# R7FA6T2BD register map
Vendor: Renesas Electronics Corporation; Series: RA6; File version: 1.30.01
CPU: CM33 r0p4, little endian, MPU, FPU, VTOR, 4 interrupt priority bits, 96 interrupts
Registers are 32-bit, read-write, reset 0x0 unless marked. A register's access mark holds for its fields unless they carry their own. Offsets are from the block's base; [hi:lo] are bit positions; {n}, {i} and the like mark numbered series; 'fields as' and 'values as' point back to an identical list.

## POEG — Port Output Enable for GPT
Base 0x4008A000
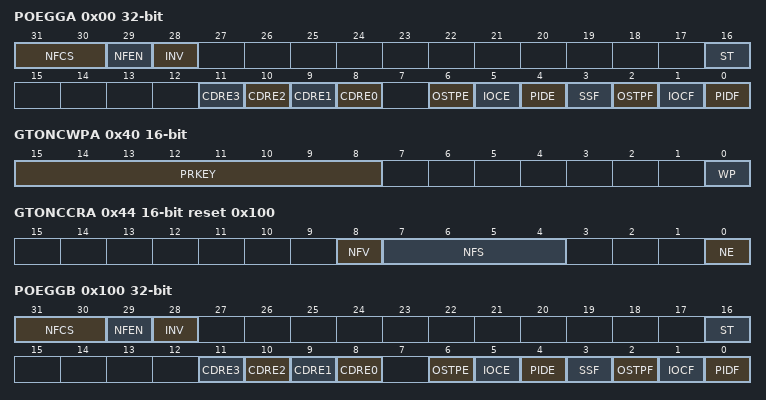
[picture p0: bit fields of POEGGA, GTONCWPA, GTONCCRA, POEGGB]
0x00 POEGGA — POEG Group A Setting Register
  [31:30] NFCS — Noise filter Clock Select
    0=Samples the input level of GTETRGn pin three times per PCLKB/1 clock; 1=Samples the input level of GTETRGn pin three times per PCLKB/8 clock; 2=Samples the input level of GTETRGn pin three times per PCLKB/32 clock; 3=Samples the input level of GTETRGn pin three times per PCLKB/128 clock
  [29] NFEN — Noise filter Enable
    0=Digital noise filter on the GTETRGn pin is disabled; 1=Digital noise filter on the GTETRGn pin is enabled
  [28] INV — GTETRGn Input Inverting
    0=Input on the GTETRGn pin is not inverted; 1=Input on the GTETRGn pin is inverted
  [16] ST ro — GTETRGn Input Status Flag
    0=The corresponding external trigger for output to the GPT is 0; 1=The corresponding external trigger for output to the GPT is 1
  [n+8] CDRE{n} (n=0..3) — ACMPHS{n} Enable
    0=Comparator edge detection {n} is disabled; 1=Comparator edge detection {n} is enabled
  [6] OSTPE — Enable Stopping Output on Stopping of Oscillation
    0=Detection of stopping of oscillation is disabled; 1=Detection of stopping of oscillation is enabled
  [5] IOCE — GPT Output Stop Request Enable
    0=Detection of stopping of output from the GPT is disabled; 1=Detection of stopping of output from the GPT is enabled
  [4] PIDE — Port Input Detection Enable
    0=Detection of input levels on the corresponding GTETRGn pin is disabled; 1=Detection of input levels on the corresponding GTETRGn pin is enabled
  [3] SSF — Software Stop Flag
    0=Software has not stopped output; 1=Software has stopped output
  [2] OSTPF — Oscillation Stop Detection Flag
    0=Stopping of oscillation was not detected; 1=Stopping of oscillation was detected
  [1] IOCF — GPT or ACMPHS Output Stop Request Detection Flag
    0=Neither stopping of GPT output nor a comparator edge was detected; 1=Either stopping of GPT output or comparator edge was detected
  [0] PIDF — Port Input Detection Flag
    0=The selected input level was not detected on the GTETRGn pin; 1=The selected input level was detected on the GTETRGn pin
0x40 GTONCWPA 16-bit — GPT Output Stopping Control Group A Write Protection Register
  [15:8] PRKEY — Key Code
  [0] WP — Register Writing Disable
    0=Writing to the GTONCCRn register is enabled; 1=Writing to the GTONCCRn register is disabled
0x44 GTONCCRA 16-bit reset 0x100 — GPT Output Stopping Control Group A Controlling Register
  [8] NFV — Direct Stopping Request Active Sense
    0=Stopping output is requested when the output stopping detection signal is 0; 1=Stopping output is requested when the output stopping detection signal is 1
  [7:4] NFS — Direct Stopping Request Selection
    0=Comparator level detection 0; 1=Comparator level detection 1; 2=Comparator level detection 2; 4=Comparator level detection 3; 7=GTETRGn pin input level detection (n = A to D); other=Others (Setting prohibited)
  [0] NE — Direct Stopping Request Setting
    0=The signal for detection is not set as a direct stopping request signal; 1=The signal for detection is set as a direct stopping request signal
0x100 POEGGB — POEG Group B Setting Register
  fields as POEGGA
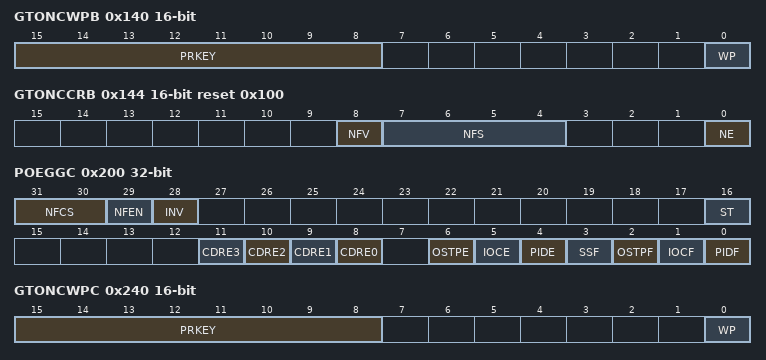
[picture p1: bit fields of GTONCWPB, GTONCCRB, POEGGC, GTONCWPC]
0x140 GTONCWPB 16-bit — GPT Output Stopping Control Group B Write Protection Register
  fields as GTONCWPA
0x144 GTONCCRB 16-bit reset 0x100 — GPT Output Stopping Control Group B Controlling Register
  fields as GTONCCRA
0x200 POEGGC — POEG Group C Setting Register
  fields as POEGGA
0x240 GTONCWPC 16-bit — GPT Output Stopping Control Group C Write Protection Register
  fields as GTONCWPA
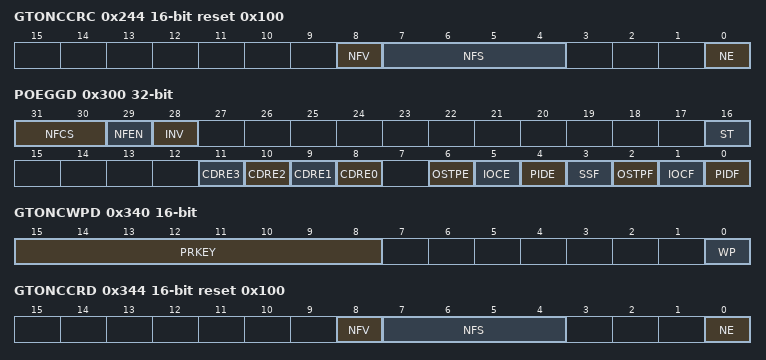
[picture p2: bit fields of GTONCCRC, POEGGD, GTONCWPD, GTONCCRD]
0x244 GTONCCRC 16-bit reset 0x100 — GPT Output Stopping Control Group C Controlling Register
  fields as GTONCCRA
0x300 POEGGD — POEG Group D Setting Register
  fields as POEGGA
0x340 GTONCWPD 16-bit — GPT Output Stopping Control Group D Write Protection Register
  fields as GTONCWPA
0x344 GTONCCRD 16-bit reset 0x100 — GPT Output Stopping Control Group D Controlling Register
  fields as GTONCCRA
